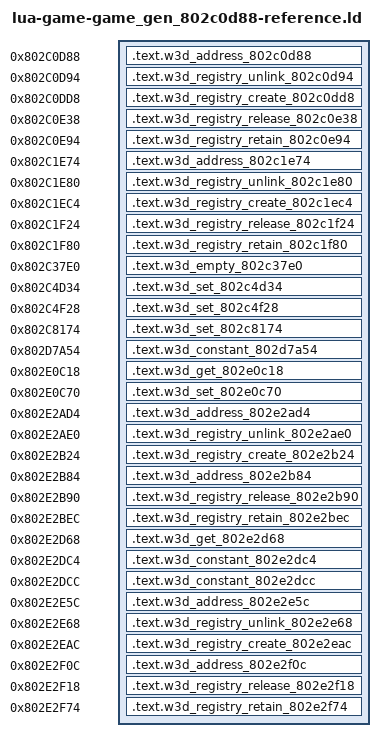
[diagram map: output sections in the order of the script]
/* Generated reference-only placements. All bodies are source-built. */
OUTPUT_FORMAT("elf32-powerpc")
OUTPUT_ARCH(powerpc)
ENTRY(w3d_address_802c0d88)
_SDA_BASE_ = 0x804b2540;
_SDA2_BASE_ = 0x804c2540;
w3d_fn_802c0eac = 0x802c0eac;
w3d_fn_802c0f68 = 0x802c0f68;
w3d_fn_802c1f98 = 0x802c1f98;
w3d_fn_802c2184 = 0x802c2184;
w3d_fn_802e2c4c = 0x802e2c4c;
w3d_fn_802e2ca0 = 0x802e2ca0;
w3d_fn_802e2fd4 = 0x802e2fd4;
w3d_fn_802e3020 = 0x802e3020;
w3d_global_80368b78 = 0x80368b78;
w3d_global_80368ba8 = 0x80368ba8;
w3d_global_80368c38 = 0x80368c38;
w3d_global_80368c68 = 0x80368c68;
w3d_global_803db3f0 = 0x803db3f0;
w3d_global_803db414 = 0x803db414;
w3d_heap_allocate_entry_a = 0x801fe1d8;
w3d_owner_list_remove = 0x8020fd2c;
w3d_registry_list_80368b78 = 0x80368b78;
w3d_registry_list_80368ba8 = 0x80368ba8;
w3d_registry_list_80368c38 = 0x80368c38;
w3d_registry_list_80368c68 = 0x80368c68;
w3d_state_register = 0x8020fd04;
SECTIONS {
  .text.w3d_address_802c0d88 0x802c0d88 : { *(.text.w3d_address_802c0d88) }
  .text.w3d_registry_unlink_802c0d94 0x802c0d94 : { *(.text.w3d_registry_unlink_802c0d94) }
  .text.w3d_registry_create_802c0dd8 0x802c0dd8 : { *(.text.w3d_registry_create_802c0dd8) }
  .text.w3d_registry_release_802c0e38 0x802c0e38 : { *(.text.w3d_registry_release_802c0e38) }
  .text.w3d_registry_retain_802c0e94 0x802c0e94 : { *(.text.w3d_registry_retain_802c0e94) }
  .text.w3d_address_802c1e74 0x802c1e74 : { *(.text.w3d_address_802c1e74) }
  .text.w3d_registry_unlink_802c1e80 0x802c1e80 : { *(.text.w3d_registry_unlink_802c1e80) }
  .text.w3d_registry_create_802c1ec4 0x802c1ec4 : { *(.text.w3d_registry_create_802c1ec4) }
  .text.w3d_registry_release_802c1f24 0x802c1f24 : { *(.text.w3d_registry_release_802c1f24) }
  .text.w3d_registry_retain_802c1f80 0x802c1f80 : { *(.text.w3d_registry_retain_802c1f80) }
  .text.w3d_empty_802c37e0 0x802c37e0 : { *(.text.w3d_empty_802c37e0) }
  .text.w3d_set_802c4d34 0x802c4d34 : { *(.text.w3d_set_802c4d34) }
  .text.w3d_set_802c4f28 0x802c4f28 : { *(.text.w3d_set_802c4f28) }
  .text.w3d_set_802c8174 0x802c8174 : { *(.text.w3d_set_802c8174) }
  .text.w3d_constant_802d7a54 0x802d7a54 : { *(.text.w3d_constant_802d7a54) }
  .text.w3d_get_802e0c18 0x802e0c18 : { *(.text.w3d_get_802e0c18) }
  .text.w3d_set_802e0c70 0x802e0c70 : { *(.text.w3d_set_802e0c70) }
  .text.w3d_address_802e2ad4 0x802e2ad4 : { *(.text.w3d_address_802e2ad4) }
  .text.w3d_registry_unlink_802e2ae0 0x802e2ae0 : { *(.text.w3d_registry_unlink_802e2ae0) }
  .text.w3d_registry_create_802e2b24 0x802e2b24 : { *(.text.w3d_registry_create_802e2b24) }
  .text.w3d_address_802e2b84 0x802e2b84 : { *(.text.w3d_address_802e2b84) }
  .text.w3d_registry_release_802e2b90 0x802e2b90 : { *(.text.w3d_registry_release_802e2b90) }
  .text.w3d_registry_retain_802e2bec 0x802e2bec : { *(.text.w3d_registry_retain_802e2bec) }
  .text.w3d_get_802e2d68 0x802e2d68 : { *(.text.w3d_get_802e2d68) }
  .text.w3d_constant_802e2dc4 0x802e2dc4 : { *(.text.w3d_constant_802e2dc4) }
  .text.w3d_constant_802e2dcc 0x802e2dcc : { *(.text.w3d_constant_802e2dcc) }
  .text.w3d_address_802e2e5c 0x802e2e5c : { *(.text.w3d_address_802e2e5c) }
  .text.w3d_registry_unlink_802e2e68 0x802e2e68 : { *(.text.w3d_registry_unlink_802e2e68) }
  .text.w3d_registry_create_802e2eac 0x802e2eac : { *(.text.w3d_registry_create_802e2eac) }
  .text.w3d_address_802e2f0c 0x802e2f0c : { *(.text.w3d_address_802e2f0c) }
  .text.w3d_registry_release_802e2f18 0x802e2f18 : { *(.text.w3d_registry_release_802e2f18) }
  .text.w3d_registry_retain_802e2f74 0x802e2f74 : { *(.text.w3d_registry_retain_802e2f74) }
  /DISCARD/ : { *(.text*) *(.rodata*) *(.data*) *(.bss*) *(.sdata*) *(.sbss*) *(.comment) }
}
